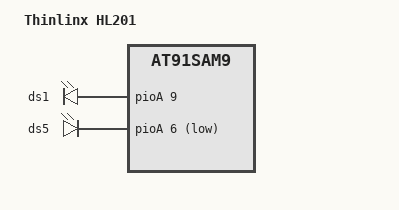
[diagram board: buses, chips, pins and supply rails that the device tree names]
/* $MidnightBSD$ */
/*
 * Hot-e HL-201 - Warner Losh public domain
 *
 * $FreeBSD: stable/10/sys/boot/fdt/dts/arm/hl201.dts 266277 2014-05-17 00:53:12Z ian $
 */
/dts-v1/;

/*
 * The following is a white lie. The HL-201 is a stripped down version of
 * the SAM9G20EK board with a video output chip.
 */
#include "at91sam9g20ek_common.dtsi"

/ {
	model = "Thinlinx HL201";
	compatible = "thinlinx,hl201", "atmel,at91sam9g20ek", "atmel,at91sam9g20", "atmel,at91sam9";

	leds {
		compatible = "gpio-leds";

		ds1 {
			label = "ds1";
			gpios = <&pioA 9 0>;
			linux,default-trigger = "heartbeat";
		};

		ds5 {
			label = "ds5";
			gpios = <&pioA 6 1>;
		};
	};

	/* Missing: one wire serial number, video chip */

	aliases {
		dbgu = &dbgu;
	};


	chosen {
		stdin = "dbgu";
		stdout = "dbgu";
	};
};
